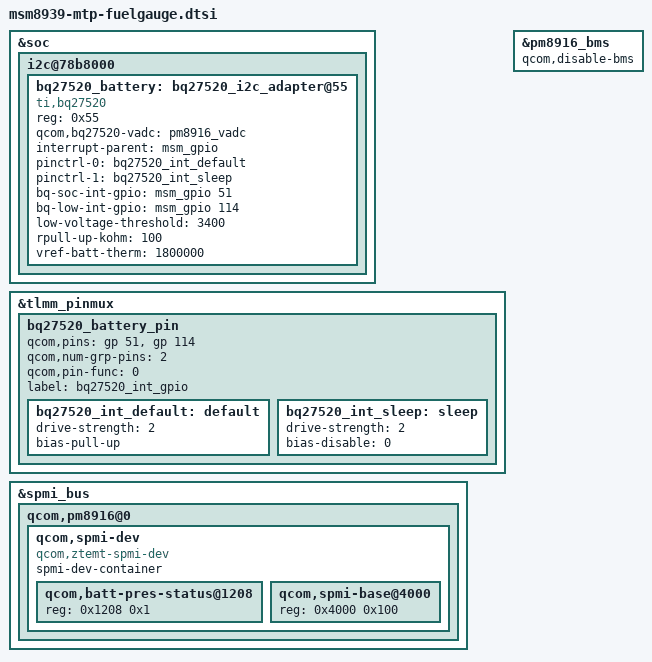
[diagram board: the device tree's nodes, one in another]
/* Copyright (c) 2014, The Linux Foundation. All rights reserved.
 *
 * This program is free software; you can redistribute it and/or modify
 * it under the terms of the GNU General Public License version 2 and
 * only version 2 as published by the Free Software Foundation.
 *
 * This program is distributed in the hope that it will be useful,
 * but WITHOUT ANY WARRANTY; without even the implied warranty of
 * MERCHANTABILITY or FITNESS FOR A PARTICULAR PURPOSE.  See the
 * GNU General Public License for more details.
 */

//add by swang  ZTEMT_BQ27520_BATTERY

&soc {
	i2c@78b8000 { /* BLSP1 QUP4   */
        bq27520_battery: bq27520_i2c_adapter@55 {
			compatible = "ti,bq27520";
			reg = <0x55>;
			qcom,bq27520-vadc = <&pm8916_vadc>;
			interrupt-parent = <&msm_gpio>;
			interrupt-names = "bq27520_irq";
			pinctrl-names = "bq27520_int_default","bq27520_int_sleep";
 			pinctrl-0 = <&bq27520_int_default>;
			pinctrl-1 = <&bq27520_int_sleep>;
 			bq-soc-int-gpio = <&msm_gpio 51 0x00>;
 			bq-low-int-gpio = <&msm_gpio 114 0x00>;
			low-voltage-threshold = <3400>;
			rpull-up-kohm = <100>;
			vref-batt-therm = <1800000>;
		};
	};
};

&tlmm_pinmux {
	bq27520_battery_pin {
		qcom,pins = <&gp 51>, <&gp 114>;
		qcom,num-grp-pins = <2>;
		qcom,pin-func = <0>;
		label = "bq27520_int_gpio";
		/* active state */
		bq27520_int_default: default {
			drive-strength = <2>; /* 2 MA */
			bias-pull-up;		/* PULL UP*/
		};
		/*suspended state */
		bq27520_int_sleep: sleep {
			drive-strength = <2>; /* 2 MA */
			bias-disable = <0>; /* No PULL */
		};
	};	
};
&pm8916_bms {
	status = "ok";
	qcom,disable-bms;
};

&spmi_bus {
	qcom,pm8916@0 {
		qcom,spmi-dev {
			spmi-dev-container;
			compatible = "qcom,ztemt-spmi-dev";
			#address-cells = <1>;
			#size-cells = <1>;
	
			qcom,batt-pres-status@1208 {
				reg = <0x1208 0x1>;
			};
	
			qcom,spmi-base@4000 {
				reg = <0x4000 0x100>;
			};
		};
	};
};

